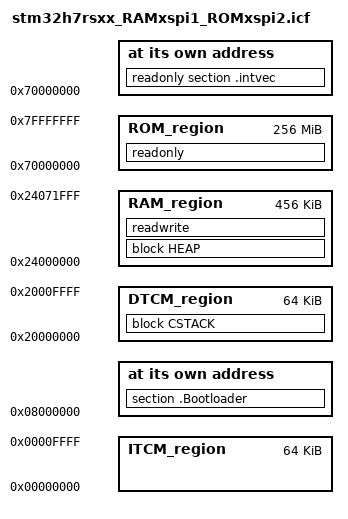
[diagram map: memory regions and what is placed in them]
/*###ICF### Section handled by ICF editor, don't touch! ****/
/*-Editor annotation file-*/
/* IcfEditorFile="$TOOLKIT_DIR$\config\ide\IcfEditor\cortex_v1_0.xml" */
/*-Specials-*/
define symbol __ICFEDIT_intvec_start__ = 0x70000000;
/*-Memory Regions-*/
define symbol __ICFEDIT_region_ROM_start__ = 0x70000000;
define symbol __ICFEDIT_region_ROM_end__   = 0x7FFFFFFF;
define symbol __ICFEDIT_region_RAM_start__ = 0x24000000;
define symbol __ICFEDIT_region_RAM_end__   = 0x24071FFF;
/*-Sizes-*/
define symbol __ICFEDIT_size_cstack__ = 0x1000;
define symbol __ICFEDIT_size_heap__   = 0x1000;
/**** End of ICF editor section. ###ICF###*/

define symbol __region_ITCM_start__    = 0x00000000;
define symbol __region_ITCM_end__      = 0x0000FFFF;
define symbol __region_DTCM_start__    = 0x20000000;
define symbol __region_DTCM_end__      = 0x2000FFFF;

define memory mem with size = 4G;
define region ROM_region      = mem:[from __ICFEDIT_region_ROM_start__ to __ICFEDIT_region_ROM_end__];
define region RAM_region      = mem:[from __ICFEDIT_region_RAM_start__ to __ICFEDIT_region_RAM_end__];
define region ITCM_region     = mem:[from __region_ITCM_start__ to __region_ITCM_end__];
define region DTCM_region     = mem:[from __region_DTCM_start__ to __region_DTCM_end__];

define block CSTACK    with alignment = 8, size = __ICFEDIT_size_cstack__   { };
define block HEAP      with alignment = 8, size = __ICFEDIT_size_heap__     { };

initialize by copy {readwrite }
    except {
        section .Bootloader  /* Don't copy Bootloader code */};

define symbol __bootloader_start__ = 0x08000000;

place at address mem:__bootloader_start__     { section .Bootloader };

place at address mem:__ICFEDIT_intvec_start__ { readonly section .intvec };

place in ROM_region   { readonly };
place in RAM_region   { block HEAP, readwrite};
place in DTCM_region  { block CSTACK };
